VERSION "DRDO PS-26054 HUMS bus - CANaerospace 1.6 - Rotax 915 i reference"

NS_ :

BS_:

BU_: ECU_A ECU_B VMC HUMS EDGE

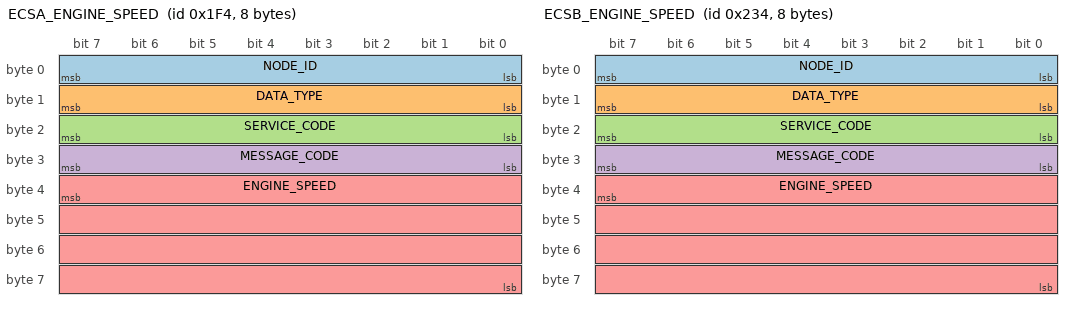
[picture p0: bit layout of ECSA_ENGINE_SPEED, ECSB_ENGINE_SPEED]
BO_ 500 ECSA_ENGINE_SPEED: 8 ECU_A
 SG_ NODE_ID : 7|8@0+ (1,0) [0|255] "" EDGE
 SG_ DATA_TYPE : 15|8@0+ (1,0) [0|255] "" EDGE
 SG_ SERVICE_CODE : 23|8@0+ (1,0) [0|255] "" EDGE
 SG_ MESSAGE_CODE : 31|8@0+ (1,0) [0|255] "" EDGE
 SG_ ENGINE_SPEED : 39|32@0+ (1,0) [0|6500] "1/min" EDGE
BO_ 564 ECSB_ENGINE_SPEED: 8 ECU_B
 SG_ NODE_ID : 7|8@0+ (1,0) [0|255] "" EDGE
 SG_ DATA_TYPE : 15|8@0+ (1,0) [0|255] "" EDGE
 SG_ SERVICE_CODE : 23|8@0+ (1,0) [0|255] "" EDGE
 SG_ MESSAGE_CODE : 31|8@0+ (1,0) [0|255] "" EDGE
 SG_ ENGINE_SPEED : 39|32@0+ (1,0) [0|6500] "1/min" EDGE
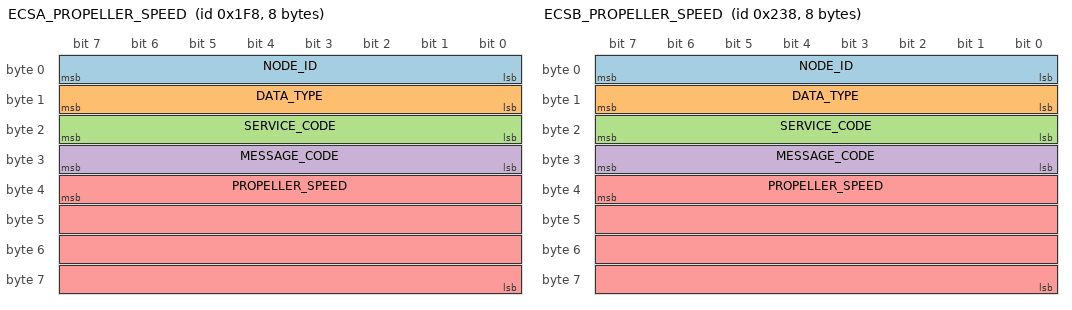
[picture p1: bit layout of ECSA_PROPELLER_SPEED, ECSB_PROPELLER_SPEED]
BO_ 504 ECSA_PROPELLER_SPEED: 8 ECU_A
 SG_ NODE_ID : 7|8@0+ (1,0) [0|255] "" EDGE
 SG_ DATA_TYPE : 15|8@0+ (1,0) [0|255] "" EDGE
 SG_ SERVICE_CODE : 23|8@0+ (1,0) [0|255] "" EDGE
 SG_ MESSAGE_CODE : 31|8@0+ (1,0) [0|255] "" EDGE
 SG_ PROPELLER_SPEED : 39|32@0+ (1,0) [0|3000] "1/min" EDGE
BO_ 568 ECSB_PROPELLER_SPEED: 8 ECU_B
 SG_ NODE_ID : 7|8@0+ (1,0) [0|255] "" EDGE
 SG_ DATA_TYPE : 15|8@0+ (1,0) [0|255] "" EDGE
 SG_ SERVICE_CODE : 23|8@0+ (1,0) [0|255] "" EDGE
 SG_ MESSAGE_CODE : 31|8@0+ (1,0) [0|255] "" EDGE
 SG_ PROPELLER_SPEED : 39|32@0+ (1,0) [0|3000] "1/min" EDGE
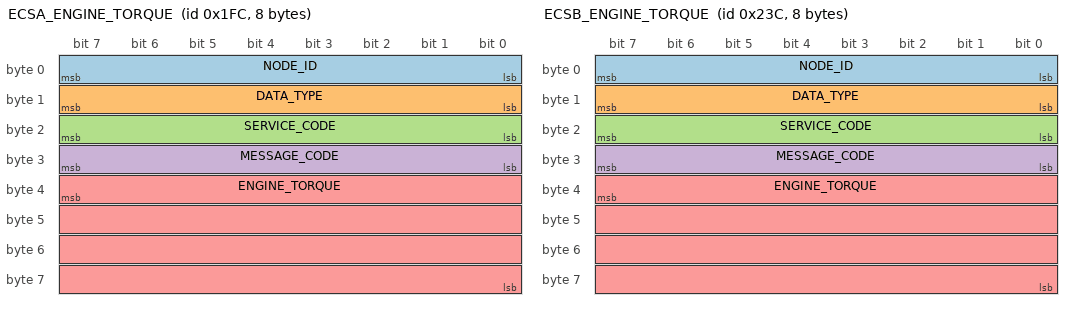
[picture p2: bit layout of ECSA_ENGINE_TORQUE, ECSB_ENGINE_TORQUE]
BO_ 508 ECSA_ENGINE_TORQUE: 8 ECU_A
 SG_ NODE_ID : 7|8@0+ (1,0) [0|255] "" EDGE
 SG_ DATA_TYPE : 15|8@0+ (1,0) [0|255] "" EDGE
 SG_ SERVICE_CODE : 23|8@0+ (1,0) [0|255] "" EDGE
 SG_ MESSAGE_CODE : 31|8@0+ (1,0) [0|255] "" EDGE
 SG_ ENGINE_TORQUE : 39|32@0+ (1,0) [0|2] "Norm" EDGE
BO_ 572 ECSB_ENGINE_TORQUE: 8 ECU_B
 SG_ NODE_ID : 7|8@0+ (1,0) [0|255] "" EDGE
 SG_ DATA_TYPE : 15|8@0+ (1,0) [0|255] "" EDGE
 SG_ SERVICE_CODE : 23|8@0+ (1,0) [0|255] "" EDGE
 SG_ MESSAGE_CODE : 31|8@0+ (1,0) [0|255] "" EDGE
 SG_ ENGINE_TORQUE : 39|32@0+ (1,0) [0|2] "Norm" EDGE
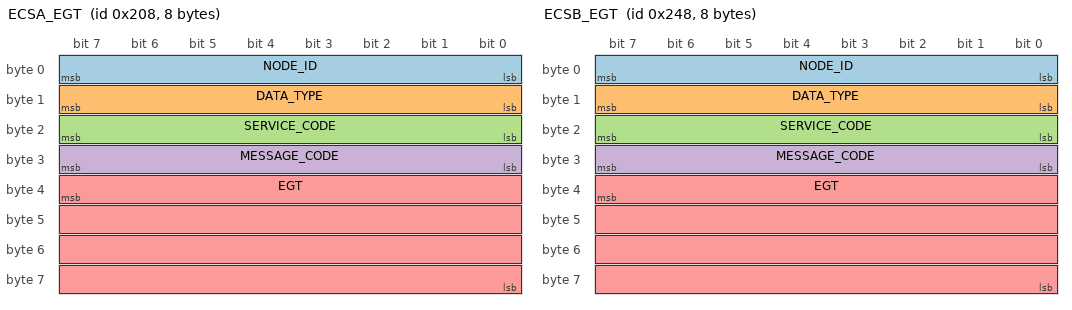
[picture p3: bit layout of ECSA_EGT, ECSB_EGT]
BO_ 520 ECSA_EGT: 8 ECU_A
 SG_ NODE_ID : 7|8@0+ (1,0) [0|255] "" EDGE
 SG_ DATA_TYPE : 15|8@0+ (1,0) [0|255] "" EDGE
 SG_ SERVICE_CODE : 23|8@0+ (1,0) [0|255] "" EDGE
 SG_ MESSAGE_CODE : 31|8@0+ (1,0) [0|255] "" EDGE
 SG_ EGT : 39|32@0+ (1,0) [0|1500] "K" EDGE
BO_ 584 ECSB_EGT: 8 ECU_B
 SG_ NODE_ID : 7|8@0+ (1,0) [0|255] "" EDGE
 SG_ DATA_TYPE : 15|8@0+ (1,0) [0|255] "" EDGE
 SG_ SERVICE_CODE : 23|8@0+ (1,0) [0|255] "" EDGE
 SG_ MESSAGE_CODE : 31|8@0+ (1,0) [0|255] "" EDGE
 SG_ EGT : 39|32@0+ (1,0) [0|1500] "K" EDGE
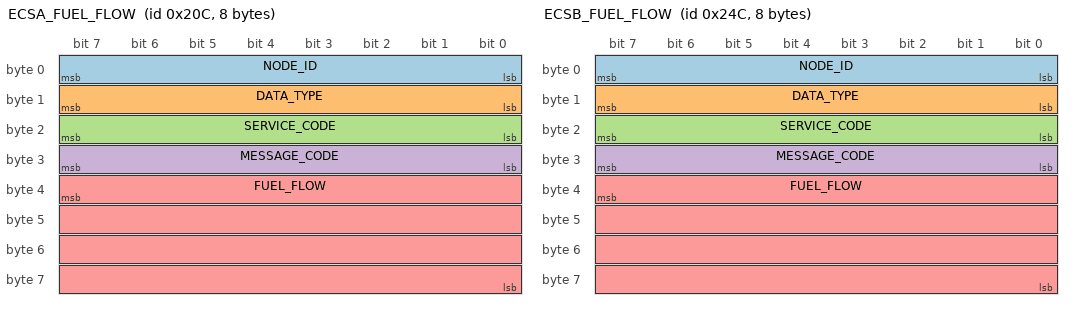
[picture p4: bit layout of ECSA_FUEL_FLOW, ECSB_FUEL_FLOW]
BO_ 524 ECSA_FUEL_FLOW: 8 HUMS
 SG_ NODE_ID : 7|8@0+ (1,0) [0|255] "" EDGE
 SG_ DATA_TYPE : 15|8@0+ (1,0) [0|255] "" EDGE
 SG_ SERVICE_CODE : 23|8@0+ (1,0) [0|255] "" EDGE
 SG_ MESSAGE_CODE : 31|8@0+ (1,0) [0|255] "" EDGE
 SG_ FUEL_FLOW : 39|32@0+ (1,0) [-5|75] "l/h" EDGE
BO_ 588 ECSB_FUEL_FLOW: 8 ECU_B
 SG_ NODE_ID : 7|8@0+ (1,0) [0|255] "" EDGE
 SG_ DATA_TYPE : 15|8@0+ (1,0) [0|255] "" EDGE
 SG_ SERVICE_CODE : 23|8@0+ (1,0) [0|255] "" EDGE
 SG_ MESSAGE_CODE : 31|8@0+ (1,0) [0|255] "" EDGE
 SG_ FUEL_FLOW : 39|32@0+ (1,0) [-5|75] "l/h" EDGE
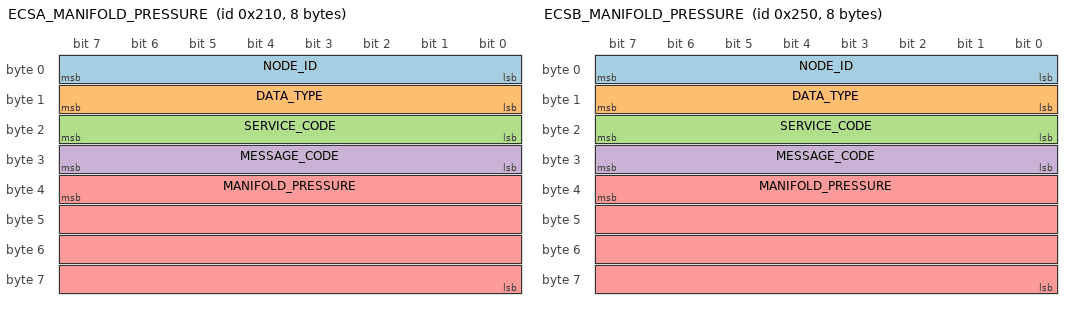
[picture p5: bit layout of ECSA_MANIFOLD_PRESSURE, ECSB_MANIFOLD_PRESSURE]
BO_ 528 ECSA_MANIFOLD_PRESSURE: 8 ECU_A
 SG_ NODE_ID : 7|8@0+ (1,0) [0|255] "" EDGE
 SG_ DATA_TYPE : 15|8@0+ (1,0) [0|255] "" EDGE
 SG_ SERVICE_CODE : 23|8@0+ (1,0) [0|255] "" EDGE
 SG_ MESSAGE_CODE : 31|8@0+ (1,0) [0|255] "" EDGE
 SG_ MANIFOLD_PRESSURE : 39|32@0+ (1,0) [0|2000] "hPa" EDGE
BO_ 592 ECSB_MANIFOLD_PRESSURE: 8 ECU_B
 SG_ NODE_ID : 7|8@0+ (1,0) [0|255] "" EDGE
 SG_ DATA_TYPE : 15|8@0+ (1,0) [0|255] "" EDGE
 SG_ SERVICE_CODE : 23|8@0+ (1,0) [0|255] "" EDGE
 SG_ MESSAGE_CODE : 31|8@0+ (1,0) [0|255] "" EDGE
 SG_ MANIFOLD_PRESSURE : 39|32@0+ (1,0) [0|2000] "hPa" EDGE
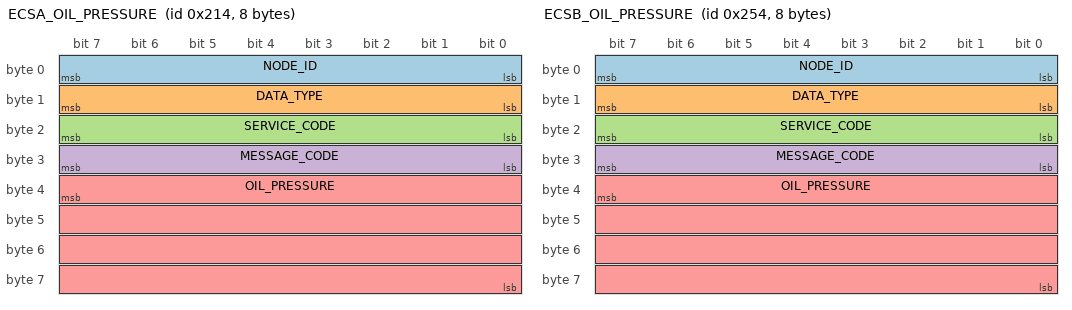
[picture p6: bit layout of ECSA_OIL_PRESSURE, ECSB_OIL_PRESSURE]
BO_ 532 ECSA_OIL_PRESSURE: 8 ECU_A
 SG_ NODE_ID : 7|8@0+ (1,0) [0|255] "" EDGE
 SG_ DATA_TYPE : 15|8@0+ (1,0) [0|255] "" EDGE
 SG_ SERVICE_CODE : 23|8@0+ (1,0) [0|255] "" EDGE
 SG_ MESSAGE_CODE : 31|8@0+ (1,0) [0|255] "" EDGE
 SG_ OIL_PRESSURE : 39|32@0+ (1,0) [-500|13000] "hPa" EDGE
BO_ 596 ECSB_OIL_PRESSURE: 8 ECU_B
 SG_ NODE_ID : 7|8@0+ (1,0) [0|255] "" EDGE
 SG_ DATA_TYPE : 15|8@0+ (1,0) [0|255] "" EDGE
 SG_ SERVICE_CODE : 23|8@0+ (1,0) [0|255] "" EDGE
 SG_ MESSAGE_CODE : 31|8@0+ (1,0) [0|255] "" EDGE
 SG_ OIL_PRESSURE : 39|32@0+ (1,0) [-500|13000] "hPa" EDGE
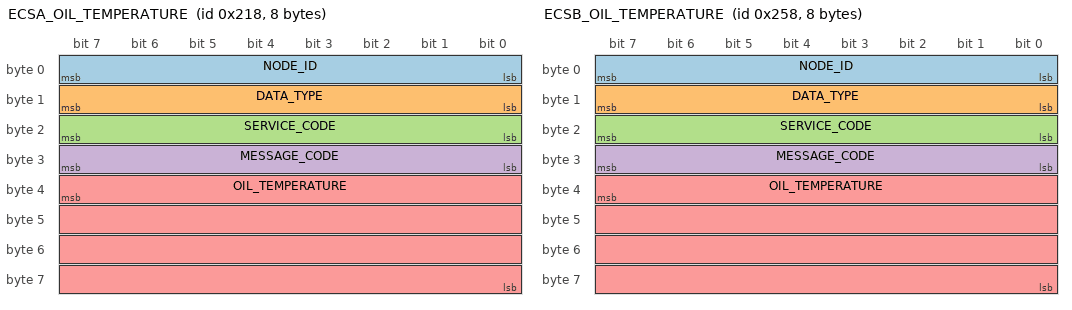
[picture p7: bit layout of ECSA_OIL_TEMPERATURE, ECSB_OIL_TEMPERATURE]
BO_ 536 ECSA_OIL_TEMPERATURE: 8 ECU_A
 SG_ NODE_ID : 7|8@0+ (1,0) [0|255] "" EDGE
 SG_ DATA_TYPE : 15|8@0+ (1,0) [0|255] "" EDGE
 SG_ SERVICE_CODE : 23|8@0+ (1,0) [0|255] "" EDGE
 SG_ MESSAGE_CODE : 31|8@0+ (1,0) [0|255] "" EDGE
 SG_ OIL_TEMPERATURE : 39|32@0+ (1,0) [200|500] "K" EDGE
BO_ 600 ECSB_OIL_TEMPERATURE: 8 ECU_B
 SG_ NODE_ID : 7|8@0+ (1,0) [0|255] "" EDGE
 SG_ DATA_TYPE : 15|8@0+ (1,0) [0|255] "" EDGE
 SG_ SERVICE_CODE : 23|8@0+ (1,0) [0|255] "" EDGE
 SG_ MESSAGE_CODE : 31|8@0+ (1,0) [0|255] "" EDGE
 SG_ OIL_TEMPERATURE : 39|32@0+ (1,0) [200|500] "K" EDGE
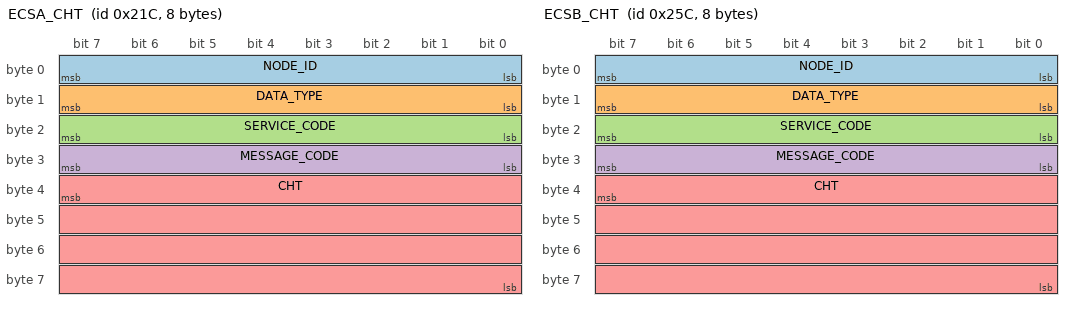
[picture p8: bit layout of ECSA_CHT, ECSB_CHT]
BO_ 540 ECSA_CHT: 8 HUMS
 SG_ NODE_ID : 7|8@0+ (1,0) [0|255] "" EDGE
 SG_ DATA_TYPE : 15|8@0+ (1,0) [0|255] "" EDGE
 SG_ SERVICE_CODE : 23|8@0+ (1,0) [0|255] "" EDGE
 SG_ MESSAGE_CODE : 31|8@0+ (1,0) [0|255] "" EDGE
 SG_ CHT : 39|32@0+ (1,0) [200|500] "K" EDGE
BO_ 604 ECSB_CHT: 8 ECU_B
 SG_ NODE_ID : 7|8@0+ (1,0) [0|255] "" EDGE
 SG_ DATA_TYPE : 15|8@0+ (1,0) [0|255] "" EDGE
 SG_ SERVICE_CODE : 23|8@0+ (1,0) [0|255] "" EDGE
 SG_ MESSAGE_CODE : 31|8@0+ (1,0) [0|255] "" EDGE
 SG_ CHT : 39|32@0+ (1,0) [200|500] "K" EDGE
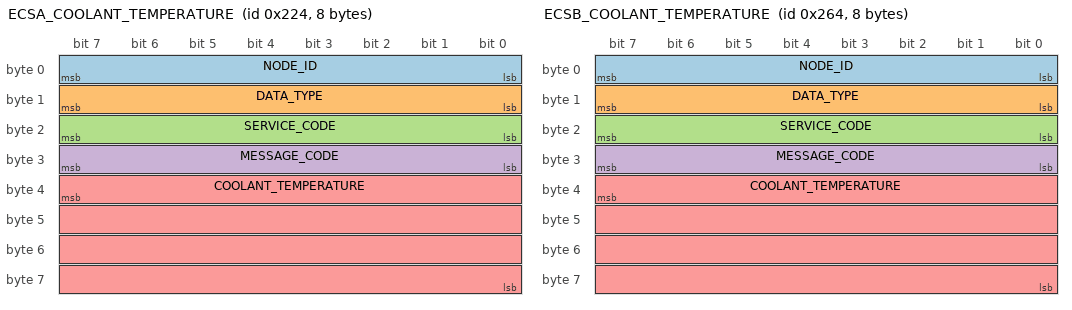
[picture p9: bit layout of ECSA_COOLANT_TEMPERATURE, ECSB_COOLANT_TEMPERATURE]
BO_ 548 ECSA_COOLANT_TEMPERATURE: 8 ECU_A
 SG_ NODE_ID : 7|8@0+ (1,0) [0|255] "" EDGE
 SG_ DATA_TYPE : 15|8@0+ (1,0) [0|255] "" EDGE
 SG_ SERVICE_CODE : 23|8@0+ (1,0) [0|255] "" EDGE
 SG_ MESSAGE_CODE : 31|8@0+ (1,0) [0|255] "" EDGE
 SG_ COOLANT_TEMPERATURE : 39|32@0+ (1,0) [200|500] "K" EDGE
BO_ 612 ECSB_COOLANT_TEMPERATURE: 8 ECU_B
 SG_ NODE_ID : 7|8@0+ (1,0) [0|255] "" EDGE
 SG_ DATA_TYPE : 15|8@0+ (1,0) [0|255] "" EDGE
 SG_ SERVICE_CODE : 23|8@0+ (1,0) [0|255] "" EDGE
 SG_ MESSAGE_CODE : 31|8@0+ (1,0) [0|255] "" EDGE
 SG_ COOLANT_TEMPERATURE : 39|32@0+ (1,0) [200|500] "K" EDGE
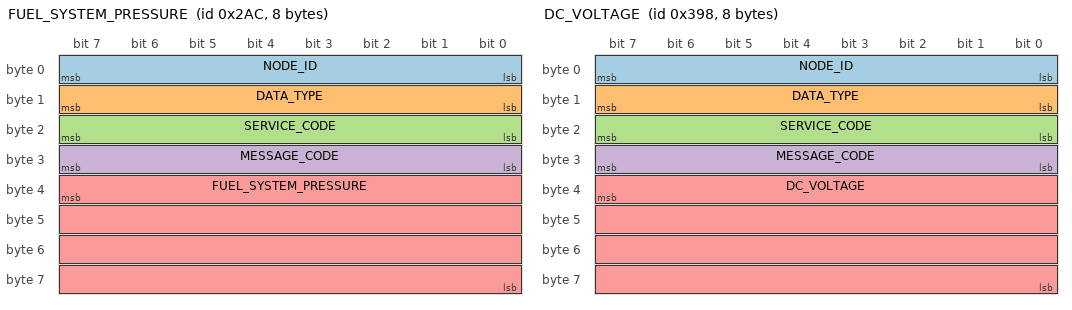
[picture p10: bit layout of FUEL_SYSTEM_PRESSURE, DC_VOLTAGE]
BO_ 684 FUEL_SYSTEM_PRESSURE: 8 ECU_A
 SG_ NODE_ID : 7|8@0+ (1,0) [0|255] "" EDGE
 SG_ DATA_TYPE : 15|8@0+ (1,0) [0|255] "" EDGE
 SG_ SERVICE_CODE : 23|8@0+ (1,0) [0|255] "" EDGE
 SG_ MESSAGE_CODE : 31|8@0+ (1,0) [0|255] "" EDGE
 SG_ FUEL_SYSTEM_PRESSURE : 39|32@0+ (1,0) [0|8000] "hPa" EDGE
BO_ 920 DC_VOLTAGE: 8 ECU_A
 SG_ NODE_ID : 7|8@0+ (1,0) [0|255] "" EDGE
 SG_ DATA_TYPE : 15|8@0+ (1,0) [0|255] "" EDGE
 SG_ SERVICE_CODE : 23|8@0+ (1,0) [0|255] "" EDGE
 SG_ MESSAGE_CODE : 31|8@0+ (1,0) [0|255] "" EDGE
 SG_ DC_VOLTAGE : 39|32@0+ (1,0) [-5|45] "V" EDGE
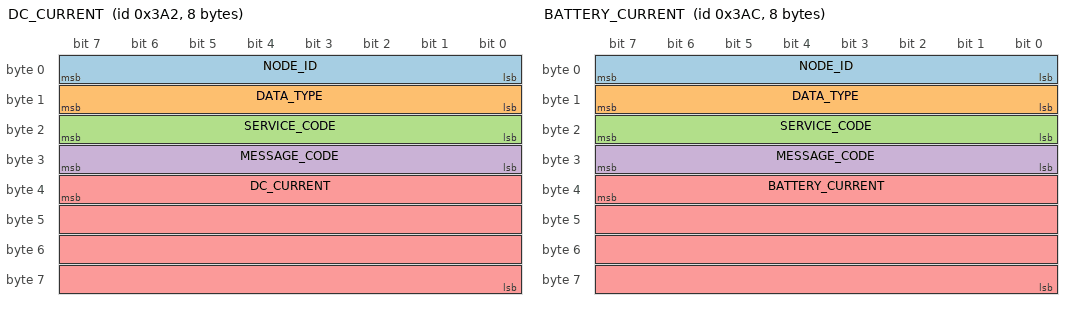
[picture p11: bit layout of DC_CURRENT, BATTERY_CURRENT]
BO_ 930 DC_CURRENT: 8 ECU_A
 SG_ NODE_ID : 7|8@0+ (1,0) [0|255] "" EDGE
 SG_ DATA_TYPE : 15|8@0+ (1,0) [0|255] "" EDGE
 SG_ SERVICE_CODE : 23|8@0+ (1,0) [0|255] "" EDGE
 SG_ MESSAGE_CODE : 31|8@0+ (1,0) [0|255] "" EDGE
 SG_ DC_CURRENT : 39|32@0+ (1,0) [-5|60] "A" EDGE
BO_ 940 BATTERY_CURRENT: 8 ECU_A
 SG_ NODE_ID : 7|8@0+ (1,0) [0|255] "" EDGE
 SG_ DATA_TYPE : 15|8@0+ (1,0) [0|255] "" EDGE
 SG_ SERVICE_CODE : 23|8@0+ (1,0) [0|255] "" EDGE
 SG_ MESSAGE_CODE : 31|8@0+ (1,0) [0|255] "" EDGE
 SG_ BATTERY_CURRENT : 39|32@0+ (1,0) [-60|60] "A" EDGE
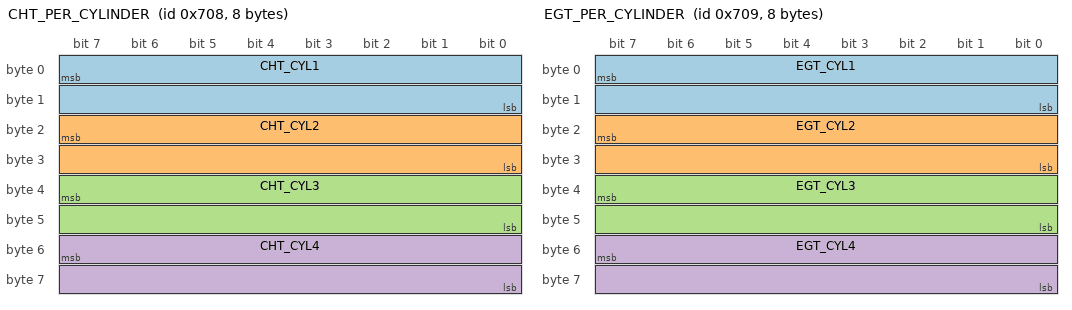
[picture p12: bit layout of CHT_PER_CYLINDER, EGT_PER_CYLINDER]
BO_ 1800 CHT_PER_CYLINDER: 8 HUMS
 SG_ CHT_CYL1 : 7|16@0+ (0.1,200) [200|500] "K" EDGE
 SG_ CHT_CYL2 : 23|16@0+ (0.1,200) [200|500] "K" EDGE
 SG_ CHT_CYL3 : 39|16@0+ (0.1,200) [200|500] "K" EDGE
 SG_ CHT_CYL4 : 55|16@0+ (0.1,200) [200|500] "K" EDGE

BO_ 1801 EGT_PER_CYLINDER: 8 HUMS
 SG_ EGT_CYL1 : 7|16@0+ (0.1,200) [200|1500] "K" EDGE
 SG_ EGT_CYL2 : 23|16@0+ (0.1,200) [200|1500] "K" EDGE
 SG_ EGT_CYL3 : 39|16@0+ (0.1,200) [200|1500] "K" EDGE
 SG_ EGT_CYL4 : 55|16@0+ (0.1,200) [200|1500] "K" EDGE

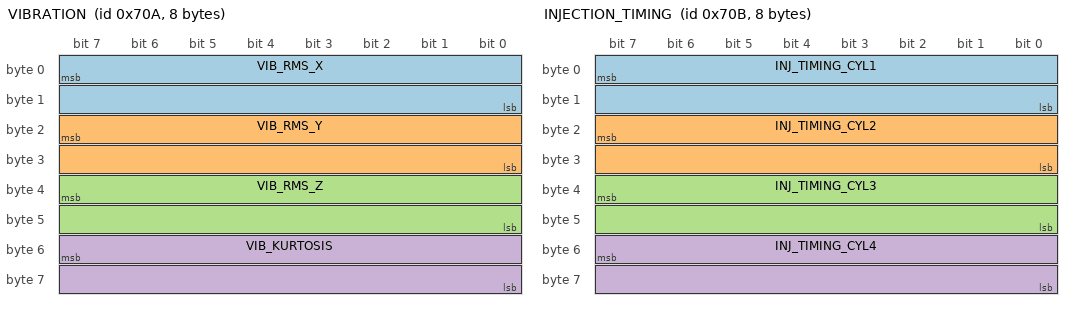
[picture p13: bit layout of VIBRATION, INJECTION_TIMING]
BO_ 1802 VIBRATION: 8 HUMS
 SG_ VIB_RMS_X : 7|16@0+ (0.01,0) [0|60] "m/s2" EDGE
 SG_ VIB_RMS_Y : 23|16@0+ (0.01,0) [0|60] "m/s2" EDGE
 SG_ VIB_RMS_Z : 39|16@0+ (0.01,0) [0|60] "m/s2" EDGE
 SG_ VIB_KURTOSIS : 55|16@0+ (0.01,0) [0|60] "m/s2" EDGE

BO_ 1803 INJECTION_TIMING: 8 HUMS
 SG_ INJ_TIMING_CYL1 : 7|16@0+ (0.1,0) [0|550] "degBTDC" EDGE
 SG_ INJ_TIMING_CYL2 : 23|16@0+ (0.1,0) [0|550] "degBTDC" EDGE
 SG_ INJ_TIMING_CYL3 : 39|16@0+ (0.1,0) [0|550] "degBTDC" EDGE
 SG_ INJ_TIMING_CYL4 : 55|16@0+ (0.1,0) [0|550] "degBTDC" EDGE

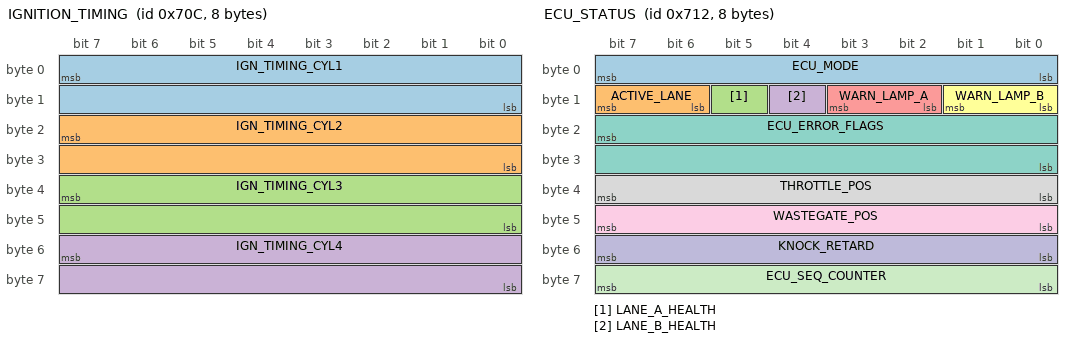
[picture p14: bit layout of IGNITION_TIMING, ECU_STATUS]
BO_ 1804 IGNITION_TIMING: 8 HUMS
 SG_ IGN_TIMING_CYL1 : 7|16@0+ (0.1,-20) [-20|60] "degBTDC" EDGE
 SG_ IGN_TIMING_CYL2 : 23|16@0+ (0.1,-20) [-20|60] "degBTDC" EDGE
 SG_ IGN_TIMING_CYL3 : 39|16@0+ (0.1,-20) [-20|60] "degBTDC" EDGE
 SG_ IGN_TIMING_CYL4 : 55|16@0+ (0.1,-20) [-20|60] "degBTDC" EDGE

BO_ 1810 ECU_STATUS: 8 ECU_A
 SG_ ECU_MODE : 7|8@0+ (1,0) [0|255] "" EDGE
 SG_ ACTIVE_LANE : 15|2@0+ (1,0) [0|3] "" EDGE
 SG_ LANE_A_HEALTH : 13|1@0+ (1,0) [0|1] "" EDGE
 SG_ LANE_B_HEALTH : 12|1@0+ (1,0) [0|1] "" EDGE
 SG_ WARN_LAMP_A : 11|2@0+ (1,0) [0|2] "" EDGE
 SG_ WARN_LAMP_B : 9|2@0+ (1,0) [0|2] "" EDGE
 SG_ ECU_ERROR_FLAGS : 23|16@0+ (1,0) [0|65535] "" EDGE
 SG_ THROTTLE_POS : 39|8@0+ (0.5,0) [0|100] "%" EDGE
 SG_ WASTEGATE_POS : 47|8@0+ (0.5,0) [0|100] "%" EDGE
 SG_ KNOCK_RETARD : 55|8@0+ (0.1,0) [0|25.5] "deg" EDGE
 SG_ ECU_SEQ_COUNTER : 63|8@0+ (1,0) [0|255] "" EDGE

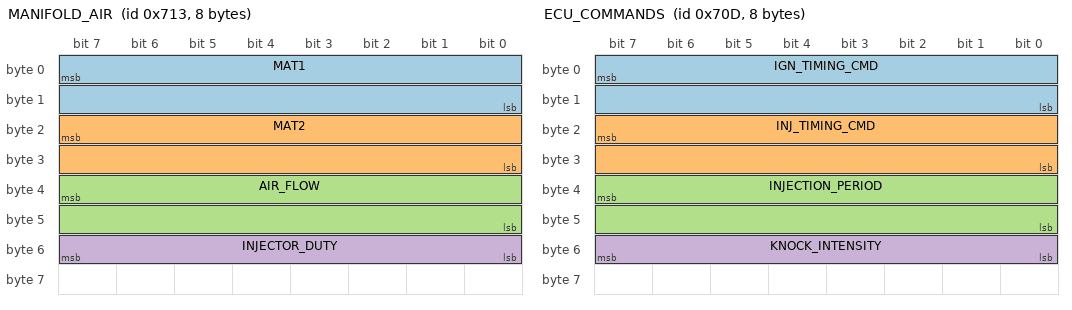
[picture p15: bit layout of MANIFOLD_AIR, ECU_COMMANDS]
BO_ 1811 MANIFOLD_AIR: 8 ECU_A
 SG_ MAT1 : 7|16@0+ (0.1,-50) [-50|150] "degC" EDGE
 SG_ MAT2 : 23|16@0+ (0.1,-50) [-50|150] "degC" EDGE
 SG_ AIR_FLOW : 39|16@0+ (1,0) [0|12000] "g/min" EDGE
 SG_ INJECTOR_DUTY : 55|8@0+ (0.5,0) [0|100] "%" EDGE

BO_ 1805 ECU_COMMANDS: 8 ECU_A
 SG_ IGN_TIMING_CMD : 7|16@0+ (0.1,-10) [-10|60] "degBTDC" EDGE
 SG_ INJ_TIMING_CMD : 23|16@0+ (0.1,0) [0|550] "degBTDC" EDGE
 SG_ INJECTION_PERIOD : 39|16@0+ (0.01,0) [0|40] "ms" EDGE
 SG_ KNOCK_INTENSITY : 55|8@0+ (0.005,0) [0|1] "" EDGE

BO_ 1813 AIRFRAME_COOLING: 8 VMC
 SG_ COOLING_FLAP_PCT : 7|8@0+ (0.5,0) [0|100] "%" EDGE
 SG_ OIL_FLAP_PCT : 15|8@0+ (0.5,0) [0|100] "%" EDGE

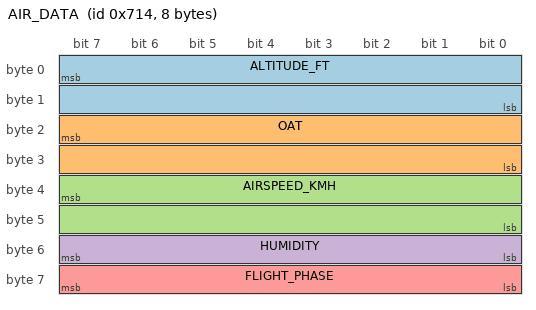
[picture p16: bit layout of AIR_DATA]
BO_ 1812 AIR_DATA: 8 VMC
 SG_ ALTITUDE_FT : 7|16@0+ (1,-1000) [-1000|40000] "ft" EDGE
 SG_ OAT : 23|16@0+ (0.1,-70) [-70|70] "degC" EDGE
 SG_ AIRSPEED_KMH : 39|16@0+ (0.1,0) [0|400] "km/h" EDGE
 SG_ HUMIDITY : 55|8@0+ (0.5,0) [0|100] "%" EDGE
 SG_ FLIGHT_PHASE : 63|8@0+ (1,0) [0|7] "" EDGE

SIG_VALTYPE_ 500 ENGINE_SPEED : 1;
SIG_VALTYPE_ 564 ENGINE_SPEED : 1;
SIG_VALTYPE_ 504 PROPELLER_SPEED : 1;
SIG_VALTYPE_ 568 PROPELLER_SPEED : 1;
SIG_VALTYPE_ 508 ENGINE_TORQUE : 1;
SIG_VALTYPE_ 572 ENGINE_TORQUE : 1;
SIG_VALTYPE_ 520 EGT : 1;
SIG_VALTYPE_ 584 EGT : 1;
SIG_VALTYPE_ 524 FUEL_FLOW : 1;
SIG_VALTYPE_ 588 FUEL_FLOW : 1;
SIG_VALTYPE_ 528 MANIFOLD_PRESSURE : 1;
SIG_VALTYPE_ 592 MANIFOLD_PRESSURE : 1;
SIG_VALTYPE_ 532 OIL_PRESSURE : 1;
SIG_VALTYPE_ 596 OIL_PRESSURE : 1;
SIG_VALTYPE_ 536 OIL_TEMPERATURE : 1;
SIG_VALTYPE_ 600 OIL_TEMPERATURE : 1;
SIG_VALTYPE_ 540 CHT : 1;
SIG_VALTYPE_ 604 CHT : 1;
SIG_VALTYPE_ 548 COOLANT_TEMPERATURE : 1;
SIG_VALTYPE_ 612 COOLANT_TEMPERATURE : 1;
SIG_VALTYPE_ 684 FUEL_SYSTEM_PRESSURE : 1;
SIG_VALTYPE_ 920 DC_VOLTAGE : 1;
SIG_VALTYPE_ 930 DC_CURRENT : 1;
SIG_VALTYPE_ 940 BATTERY_CURRENT : 1;

CM_ BU_ ECU_A "Engine Control Unit Lane A. The Rotax 915 i carries a certified dual-channel FADEC for ignition and injection (EASA TCDS E.121 section 2). Lane A publishes on Display CAN Lane A via Harness Interface Connector A, and drives Warning Lamp A (12 V, 120 mA). CANaerospace calls this ECS channel A.";
CM_ BU_ ECU_B "Engine Control Unit Lane B. Independent redundant channel on Display CAN Lane B via Harness Interface Connector B, driving Warning Lamp B. CANaerospace ECS channel B, identifiers offset +64 from channel A. Having both lanes on the bus gives the ingest layer a genuine two-source cross-check, which is the cheapest and strongest sensor-validity vote available (PRD Part 1 section 8.3).";
CM_ BU_ VMC "Vehicle Management Computer. Supplies the air data the physics model needs. Not part of the engine EMS; carried in the CANaerospace user-defined range.";
CM_ BU_ HUMS "Health and Usage Monitoring instrumentation added by THIS PROJECT and not fitted to a standard 915 i: per-cylinder cylinder-head thermocouples, per-cylinder EGT breakout, a tri-axial MEMS accelerometer and a turbine fuel-flow meter. Declared separately so no reader mistakes added instrumentation for factory capability.";
CM_ BU_ EDGE "Edge node. Raspberry Pi 4 / Jetson class with a CAN interface in the production build; python-can virtual bus in the demo (decision D1).";
CM_ BO_ 500 "CANaerospace ID 500 (ECS channel A). Engine N1. For a piston engine this is crankshaft RPM. Idle minimum 1800 rpm, max continuous 5500 rpm, take-off 5800 rpm for 5 minutes (EASA TCDS E.121). Sampled at 100 Hz for per-power-stroke misfire detection (PRD Part 2 section 10.1 Method A).";
CM_ BO_ 564 "CANaerospace ID 564 (ECS channel B, +64 offset). Redundant lane of ID 500.";
CM_ BO_ 504 "CANaerospace ID 504 (ECS channel A). Engine N2. Propeller shaft speed = crankshaft / 2.5454 reduction ratio (EASA TCDS E.121).";
CM_ BO_ 568 "CANaerospace ID 568 (ECS channel B, +64 offset). Redundant lane of ID 504.";
CM_ BO_ 508 "CANaerospace ID 508 (ECS channel A). Normalised engine torque.";
CM_ BO_ 572 "CANaerospace ID 572 (ECS channel B, +64 offset). Redundant lane of ID 508.";
CM_ BO_ 520 "CANaerospace ID 520 (ECS channel A). Exhaust gas temperature. Certified limit 950 degC; certified EGT-split limit 200 degC above 3 L/hr fuel flow and 500 degC below it (OM-915 i Ed.0 Rev.4 section 2.1). CANaerospace assigns ONE identifier per engine, so this frame carries the highest of the four probes; the per-cylinder detail travels in the user-defined range.";
CM_ BO_ 584 "CANaerospace ID 584 (ECS channel B, +64 offset). Redundant lane of ID 520.";
CM_ BO_ 524 "CANaerospace ID 524 (ECS channel A). Fuel flow rate.";
CM_ BO_ 588 "CANaerospace ID 588 (ECS channel B, +64 offset). Redundant lane of ID 524.";
CM_ BO_ 528 "CANaerospace ID 528 (ECS channel A). Manifold absolute pressure. Range 60-1730 hPa. The boost controller targets 1450 hPa at 5500 rpm and 1520 hPa at 5800 rpm; 1730 hPa is a never-exceed authority limit, not a setpoint (OM Ed.0 Rev.4 section 2.1).";
CM_ BO_ 592 "CANaerospace ID 592 (ECS channel B, +64 offset). Redundant lane of ID 528.";
CM_ BO_ 532 "CANaerospace ID 532 (ECS channel A). Oil pressure. Normal 2.0-5.0 bar above 3500 rpm, minimum 0.8 bar below 3500 rpm, 7.0 bar tolerated briefly at cold start.";
CM_ BO_ 596 "CANaerospace ID 596 (ECS channel B, +64 offset). Redundant lane of ID 532.";
CM_ BO_ 536 "CANaerospace ID 536 (ECS channel A). Oil temperature. Normal operation 50-130 degC, 90-110 degC recommended.";
CM_ BO_ 600 "CANaerospace ID 600 (ECS channel B, +64 offset). Redundant lane of ID 536.";
CM_ BO_ 540 "CANaerospace ID 540 (ECS channel A). Cylinder head temperature. HUMS-ADDED INSTRUMENTATION: the 915 i is liquid-cooled on the heads and fits a single coolant temperature sensor on cylinder head 4 (OM section 7.2), not per-cylinder CHT. This frame carries the highest of the four added probes.";
CM_ BO_ 604 "CANaerospace ID 604 (ECS channel B, +64 offset). Redundant lane of ID 540.";
CM_ BO_ 548 "CANaerospace ID 548 (ECS channel A). Coolant temperature -- the CERTIFIED thermal limit for this engine, 120 degC in normal operation (EASA TCDS E.121, OM section 2.1). Measured by the CTS on cylinder head 4.";
CM_ BO_ 612 "CANaerospace ID 612 (ECS channel B, +64 offset). Redundant lane of ID 548.";
CM_ BO_ 684 "CANaerospace ID 684. Fuel rail pressure. Normal 2.9-3.2 bar; 2.5-3.5 bar tolerated for at most 3 s after a power-setting change (OM Ed.0 Rev.4 section 2.1).";
CM_ BO_ 920 "CANaerospace ID 920. DC system voltage. The iSc C24 variant carries a 28 V system interface (EASA TCDS E.121 section 2).";
CM_ BO_ 930 "CANaerospace ID 930. DC system current. The engine has two internal generators: Generator 1 supplies the Engine Management System, Generator 2 supplies the airframe (OM section 4.1.1).";
CM_ BO_ 940 "CANaerospace ID 940. Battery current from a pack shunt. Positive discharging, negative on charge. Required for internal-resistance estimation (PRD Part 2 section 9.2 Parameter 8).";
CM_ BO_ 1800 "User-defined (CANAS 1800-1899). Per-cylinder cylinder head temperature. HUMS-ADDED. Four 16-bit values replace the CANaerospace header+data layout because this is a user-defined message: the range 1800-1899 has an entirely user-defined format by CANAS section 2.1.";
CM_ BO_ 1801 "User-defined (CANAS 1800-1899). Per-cylinder exhaust gas temperature. Needed for the EGT-split limit and for injector-imbalance detection (PRD Part 2 section 10.2 Method B).";
CM_ BO_ 1802 "User-defined (CANAS 1800-1899). Tri-axial vibration RMS plus kurtosis. HUMS-ADDED. The raw 10 kHz waveform used for FFT, envelope and order analysis travels on the high-speed path, not on this frame.";
CM_ BO_ 1803 "User-defined (CANAS 1800-1899). Per-cylinder start-of-injection timing. REQUIRED BY THE PROBLEM STATEMENT section B ('Injection timing parameters'). On a FADEC engine this is ECU-scheduled and varies with load, speed and knock feedback, so it is monitored as a DEVIATION from the commanded value rather than against a fixed number. CANaerospace has no standard identifier for it, so it sits in the user-defined range.";
CM_ BO_ 1804 "User-defined (CANAS 1800-1899). Per-cylinder ignition timing. Not itself a problem-statement parameter, but it is what the knock sensor retards, so a diverging ignition-vs-injection timing pair is a direct combustion-quality indicator (PRD Part 2 section 10.6).";
CM_ SG_ 500 SERVICE_CODE "CANaerospace: for Normal Operation Data this byte continuously reflects the status of the data or of the transmitting unit, so the validity of every value is known at the instant it arrives. This is the bus-level input to the value-state model of PRD Part 4 section 7.1.";
CM_ SG_ 500 MESSAGE_CODE "CANaerospace: message numbering. Detects missing frames and lets a receiver compare the age of messages from redundant sources -- i.e. decide which FADEC lane is fresher. Drives the STALE state of PRD Part 4 section 7.1.";
CM_ SG_ 1810 ECU_ERROR_FLAGS "Bitfield. bit0 SENSOR_FAULT, bit1 IGNITION_FAULT, bit2 INJECTION_FAULT, bit3 OVERBOOST, bit4 KNOCK_DETECTED, bit5 WASTEGATE_FAULT, bit6 LIMP_MODE, bit7 OVERSPEED_PROTECT, bit8 LANE_A_FAULT, bit9 LANE_B_FAULT, bit10 GEN1_FAULT, bit11 GEN2_FAULT, bit12 FUEL_PRESS_FAULT, bit13 MAT_OVER_LIMIT, bit14 COOLANT_OVER_LIMIT, bit15 OIL_PRESS_LOW.";
CM_ BO_ 1805 "ECU commanded ignition and injection schedule. The bus carries what the ECU COMMANDED; messages 1803/1804 carry what the HUMS instrumentation MEASURED per cylinder. Their difference is the diagnostic quantity of PRD Part 2 section 10.2 Method C: a fouled injector opens late and its deviation grows with engine speed, because a fixed solenoid delay is more crank angle at higher rpm. Injection period is the engine primary fuel-metering command, OM-915 i Ed.0 Rev.4 section 7.5.3.";
CM_ SG_ 1810 KNOCK_RETARD "Ignition retard commanded by the knock sensor feedback loop. A rising trend at constant power is an early combustion-quality indicator (PRD Part 2 section 10.6).";
CM_ BO_ 1813 "Airframe cooling-air flap positions. This engine has NO thermostat: the manufacturer's manuals contain neither the word nor the part, so what holds coolant and oil temperature is the air the airframe admits and these are the actuators that admit it. Like the wastegate they SATURATE, and a radiator losing capacity spends this travel long before it moves a temperature: measured, losing 30 percent of the cooling air moves the flap 31.8 sensor-sigmas and the coolant 4.0.";
CM_ SG_ 1811 MAT1 "Manifold air temperature from the lane A MATS. MATS is fitted to both FADEC lanes [IM Rev.5 failure matrix].";
CM_ SG_ 1811 MAT2 "Manifold air temperature from the lane B MATS.";
CM_ SG_ 500 NODE_ID "CANaerospace: the transmitting station. A frame whose Node-ID is not a declared transmitter of the message is refused by the receiver, never decoded (audit 15 Sep, P0).";
CM_ SG_ 500 DATA_TYPE "CANaerospace data type. Every header message on this bus carries FLOAT (2). NODATA (0) or any other type is refused as a reading: a NODATA payload decodes as 0.0 and must not become one.";

BA_DEF_ BU_ "CANaerospaceNodeId" INT 0 255;
BA_DEF_DEF_ "CANaerospaceNodeId" 0;
BA_ "CANaerospaceNodeId" BU_ ECU_A 11;
BA_ "CANaerospaceNodeId" BU_ ECU_B 12;
BA_ "CANaerospaceNodeId" BU_ HUMS 20;
BA_ "CANaerospaceNodeId" BU_ VMC 30;

VAL_ 1810 ECU_MODE 0 "OFF" 1 "STARTING" 2 "RUNNING" 3 "LIMP" 4 "SHUTDOWN" 5 "FAULT" ;
VAL_ 1810 ACTIVE_LANE 0 "NONE" 1 "ONLY_A" 2 "ONLY_B" 3 "AUTO_AB" ;
VAL_ 1810 WARN_LAMP_A 0 "OFF" 1 "ON" 2 "FLASHING" ;
VAL_ 1810 WARN_LAMP_B 0 "OFF" 1 "ON" 2 "FLASHING" ;
VAL_ 1812 FLIGHT_PHASE 0 "GROUND" 1 "STARTUP" 2 "TAXI" 3 "TAKEOFF" 4 "CLIMB" 5 "CRUISE" 6 "DESCENT" 7 "LANDING" ;
